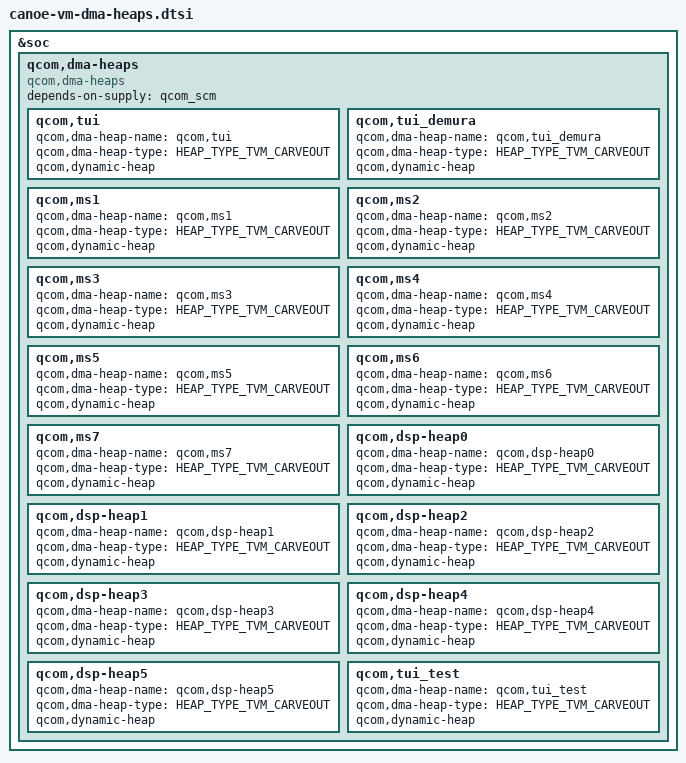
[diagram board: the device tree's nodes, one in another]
// SPDX-License-Identifier: BSD-3-Clause
/*
 * Copyright (c) 2024-2025 Qualcomm Innovation Center, Inc. All rights reserved.
 */
#include <dt-bindings/arm/msm/qcom_dma_heap_dt_constants.h>

&soc {
	qcom,dma-heaps {
		compatible = "qcom,dma-heaps";
		depends-on-supply = <&qcom_scm>;

		qcom,tui {
			qcom,dma-heap-name = "qcom,tui";
			qcom,dma-heap-type = <HEAP_TYPE_TVM_CARVEOUT>;
			qcom,dynamic-heap;
		};

		qcom,tui_demura {
			qcom,dma-heap-name = "qcom,tui_demura";
			qcom,dma-heap-type = <HEAP_TYPE_TVM_CARVEOUT>;
			qcom,dynamic-heap;
		};

		qcom,ms1 {
			qcom,dma-heap-name = "qcom,ms1";
			qcom,dma-heap-type = <HEAP_TYPE_TVM_CARVEOUT>;
			qcom,dynamic-heap;
		};

		qcom,ms2 {
			qcom,dma-heap-name = "qcom,ms2";
			qcom,dma-heap-type = <HEAP_TYPE_TVM_CARVEOUT>;
			qcom,dynamic-heap;
		};

		qcom,ms3 {
			qcom,dma-heap-name = "qcom,ms3";
			qcom,dma-heap-type = <HEAP_TYPE_TVM_CARVEOUT>;
			qcom,dynamic-heap;
		};

		qcom,ms4 {
			qcom,dma-heap-name = "qcom,ms4";
			qcom,dma-heap-type = <HEAP_TYPE_TVM_CARVEOUT>;
			qcom,dynamic-heap;
		};

		qcom,ms5 {
			qcom,dma-heap-name = "qcom,ms5";
			qcom,dma-heap-type = <HEAP_TYPE_TVM_CARVEOUT>;
			qcom,dynamic-heap;
		};

		qcom,ms6 {
			qcom,dma-heap-name = "qcom,ms6";
			qcom,dma-heap-type = <HEAP_TYPE_TVM_CARVEOUT>;
			qcom,dynamic-heap;
		};

		qcom,ms7 {
			qcom,dma-heap-name = "qcom,ms7";
			qcom,dma-heap-type = <HEAP_TYPE_TVM_CARVEOUT>;
			qcom,dynamic-heap;
		};

		qcom,dsp-heap0 {
			qcom,dma-heap-name = "qcom,dsp-heap0";
			qcom,dma-heap-type = <HEAP_TYPE_TVM_CARVEOUT>;
			qcom,dynamic-heap;
		};

		qcom,dsp-heap1 {
			qcom,dma-heap-name = "qcom,dsp-heap1";
			qcom,dma-heap-type = <HEAP_TYPE_TVM_CARVEOUT>;
			qcom,dynamic-heap;
		};

		qcom,dsp-heap2 {
			qcom,dma-heap-name = "qcom,dsp-heap2";
			qcom,dma-heap-type = <HEAP_TYPE_TVM_CARVEOUT>;
			qcom,dynamic-heap;
		};

		qcom,dsp-heap3 {
			qcom,dma-heap-name = "qcom,dsp-heap3";
			qcom,dma-heap-type = <HEAP_TYPE_TVM_CARVEOUT>;
			qcom,dynamic-heap;
		};

		qcom,dsp-heap4 {
			qcom,dma-heap-name = "qcom,dsp-heap4";
			qcom,dma-heap-type = <HEAP_TYPE_TVM_CARVEOUT>;
			qcom,dynamic-heap;
		};

		qcom,dsp-heap5 {
			qcom,dma-heap-name = "qcom,dsp-heap5";
			qcom,dma-heap-type = <HEAP_TYPE_TVM_CARVEOUT>;
			qcom,dynamic-heap;
		};

		qcom,tui_test {
			qcom,dma-heap-name = "qcom,tui_test";
			qcom,dma-heap-type = <HEAP_TYPE_TVM_CARVEOUT>;
			qcom,dynamic-heap;
		};
	};
};
